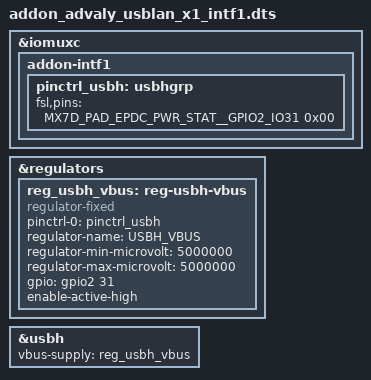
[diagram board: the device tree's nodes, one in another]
/*
 * Copyright (C) 2018 Atmark Techno, Inc. All Rights Reserved.
 * Author: Daisuke Mizobuchi <mizo@atmark-techno.com>
 *
 * This program is free software; you can redistribute it and/or
 * modify it under the terms of the GNU General Public License
 * version 2 as published by the Free Software Foundation.
 */

#include <dt-bindings/clock/imx7d-clock.h>
#include "../../../../arch/arm/boot/dts/imx7d-pinfunc.h"

/dts-v1/;
/plugin/;
/ {
	fragment@0 {
		target = <&iomuxc>;
		__overlay__ {
			addon-intf1 {
				pinctrl_usbh: usbhgrp {
					fsl,pins = <
						MX7D_PAD_EPDC_PWR_STAT__GPIO2_IO31 0x00	/* G_AOM_USB_PWREN */
					>;
				};
			};
		};
	};

	fragment@1 {
		target = <&regulators>;
		__overlay__ {
			reg_usbh_vbus: reg-usbh-vbus {
				compatible = "regulator-fixed";
				pinctrl-names = "default";
				pinctrl-0 = <&pinctrl_usbh>;
				regulator-name = "USBH_VBUS";
				regulator-min-microvolt = <5000000>;
				regulator-max-microvolt = <5000000>;
				gpio = <&gpio2 31 0>;
				enable-active-high;
			};
		};
	};

	fragment@2 {
		target = <&usbh>;
		__overlay__ {
			vbus-supply = <&reg_usbh_vbus>;
		};
	};
};
